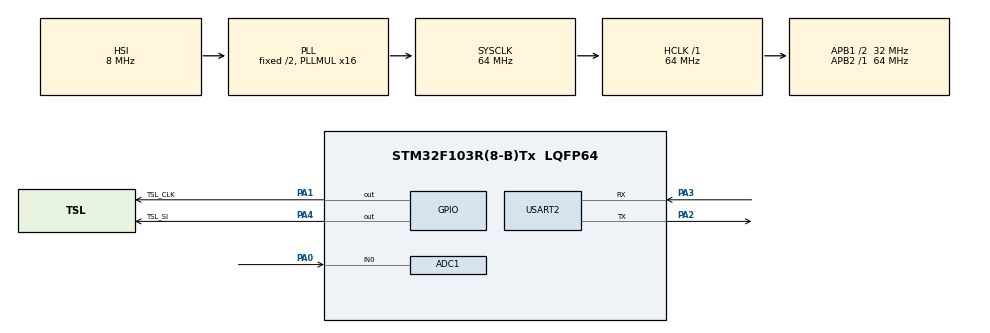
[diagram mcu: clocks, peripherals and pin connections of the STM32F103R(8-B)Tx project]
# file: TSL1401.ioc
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ADC1.Channel-0\#ChannelRegularConversion=ADC_CHANNEL_0
ADC1.NbrOfConversionFlag=1
ADC1.Rank-0\#ChannelRegularConversion=1
ADC1.SamplingTime-0\#ChannelRegularConversion=ADC_SAMPLETIME_1CYCLE_5
ADC1.master=1
Dma.Request0=USART2_RX
Dma.Request1=USART2_TX
Dma.USART2_RX.0.Direction=DMA_PERIPH_TO_MEMORY
Dma.USART2_RX.0.Instance=DMA1_Channel6
Dma.USART2_RX.0.MemDataAlignment=DMA_MDATAALIGN_BYTE
Dma.USART2_RX.0.MemInc=DMA_MINC_ENABLE
Dma.USART2_RX.0.Mode=DMA_NORMAL
Dma.USART2_RX.0.PeriphDataAlignment=DMA_PDATAALIGN_BYTE
Dma.USART2_RX.0.PeriphInc=DMA_PINC_DISABLE
Dma.USART2_RX.0.Priority=DMA_PRIORITY_LOW
Dma.USART2_TX.1.Direction=DMA_MEMORY_TO_PERIPH
Dma.USART2_TX.1.Instance=DMA1_Channel7
Dma.USART2_TX.1.MemDataAlignment=DMA_MDATAALIGN_BYTE
Dma.USART2_TX.1.MemInc=DMA_MINC_ENABLE
Dma.USART2_TX.1.Mode=DMA_NORMAL
Dma.USART2_TX.1.PeriphDataAlignment=DMA_PDATAALIGN_BYTE
Dma.USART2_TX.1.PeriphInc=DMA_PINC_DISABLE
Dma.USART2_TX.1.Priority=DMA_PRIORITY_LOW
Mcu.Family=STM32F1
Mcu.Name=STM32F103R(8-B)Tx
Mcu.Package=LQFP64
NVIC.ADC1_2_IRQn=true\:0\:0\:false\:false\:true\:true\:true\:true
NVIC.DMA1_Channel6_IRQn=true\:0\:0\:false\:false\:true\:false\:true\:true
NVIC.DMA1_Channel7_IRQn=true\:0\:0\:false\:false\:true\:false\:true\:true
NVIC.PriorityGroup=NVIC_PRIORITYGROUP_4
NVIC.USART2_IRQn=true\:0\:0\:false\:false\:true\:true\:true\:true
PA0-WKUP.Signal=ADCx_IN0
PA1.GPIO_Label=TSL_CLK
PA1.Signal=GPIO_Output
PA2.Mode=Asynchronous
PA2.Signal=USART2_TX
PA3.Mode=Asynchronous
PA3.Signal=USART2_RX
PA4.GPIO_Label=TSL_SI
PA4.Signal=GPIO_Output
ProjectManager.HeapSize=0x200
ProjectManager.StackSize=0x400
ProjectManager.TargetToolchain=Makefile
RCC.ADCPresc=RCC_ADCPCLK2_DIV8
RCC.AHBFreq_Value=64000000
RCC.APB1CLKDivider=RCC_HCLK_DIV2
RCC.APB1Freq_Value=32000000
RCC.APB1TimFreq_Value=64000000
RCC.APB2Freq_Value=64000000
RCC.APB2TimFreq_Value=64000000
RCC.HCLKFreq_Value=64000000
RCC.PLLMUL=RCC_PLL_MUL16
RCC.SYSCLKFreq_VALUE=64000000
RCC.SYSCLKSource=RCC_SYSCLKSOURCE_PLLCLK
RCC.USBFreq_Value=64000000
SH.ADCx_IN0.0=ADC1_IN0,IN0
USART2.VirtualMode=VM_ASYNC
VP_SYS_VS_ND.Mode=No_Debug
board=custom

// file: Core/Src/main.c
/* USER CODE BEGIN Header */
/**
  ******************************************************************************
  * @file           : main.c
  * @brief          : Main program body
  ******************************************************************************
  * @attention
  *
  * Copyright (c) 2023 STMicroelectronics.
  * All rights reserved.
  *
  * This software is licensed under terms that can be found in the LICENSE file
  * in the root directory of this software component.
  * If no LICENSE file comes with this software, it is provided AS-IS.
  *
  ******************************************************************************
  */
/* USER CODE END Header */
#include "main.h"
#include "adc.h"
#include "dma.h"
#include "usart.h"
#include "gpio.h"

/* USER CODE BEGIN Includes */
#include <TSL1401.h>
/* USER CODE END Includes */

void SystemClock_Config(void);

int main(void)
{

  /* MCU Configuration--------------------------------------------------------*/

  /* Reset of all peripherals, Initializes the Flash interface and the Systick. */
  HAL_Init();

  /* Configure the system clock */
  SystemClock_Config();

  /* Initialize all configured peripherals */
  MX_GPIO_Init();
  MX_DMA_Init();
  MX_ADC1_Init();
  MX_USART2_UART_Init();
  /* USER CODE BEGIN 2 */
  TSL1401Initialize();
  TSL1401EnableAutoExposure();
  TSL1401EnableContinuousExposure();
  /* USER CODE END 2 */

  /* Infinite loop */
  /* USER CODE BEGIN WHILE */
  while (1)
  {
    TSL1401AsyncReadServiceFunction();
    /* USER CODE END WHILE */

  }
}

void SystemClock_Config(void)
{
  RCC_OscInitTypeDef RCC_OscInitStruct = {0};
  RCC_ClkInitTypeDef RCC_ClkInitStruct = {0};
  RCC_PeriphCLKInitTypeDef PeriphClkInit = {0};

  /** Initializes the RCC Oscillators according to the specified parameters
  * in the RCC_OscInitTypeDef structure.
  */
  RCC_OscInitStruct.OscillatorType = RCC_OSCILLATORTYPE_HSI;
  RCC_OscInitStruct.HSIState = RCC_HSI_ON;
  RCC_OscInitStruct.HSICalibrationValue = RCC_HSICALIBRATION_DEFAULT;
  RCC_OscInitStruct.PLL.PLLState = RCC_PLL_ON;
  RCC_OscInitStruct.PLL.PLLSource = RCC_PLLSOURCE_HSI_DIV2;
  RCC_OscInitStruct.PLL.PLLMUL = RCC_PLL_MUL16;
  if (HAL_RCC_OscConfig(&RCC_OscInitStruct) != HAL_OK)
  {
    Error_Handler();
  }

  /** Initializes the CPU, AHB and APB buses clocks
  */
  RCC_ClkInitStruct.ClockType = RCC_CLOCKTYPE_HCLK|RCC_CLOCKTYPE_SYSCLK
                              |RCC_CLOCKTYPE_PCLK1|RCC_CLOCKTYPE_PCLK2;
  RCC_ClkInitStruct.SYSCLKSource = RCC_SYSCLKSOURCE_PLLCLK;
  RCC_ClkInitStruct.AHBCLKDivider = RCC_SYSCLK_DIV1;
  RCC_ClkInitStruct.APB1CLKDivider = RCC_HCLK_DIV2;
  RCC_ClkInitStruct.APB2CLKDivider = RCC_HCLK_DIV1;

  if (HAL_RCC_ClockConfig(&RCC_ClkInitStruct, FLASH_LATENCY_2) != HAL_OK)
  {
    Error_Handler();
  }
  PeriphClkInit.PeriphClockSelection = RCC_PERIPHCLK_ADC;
  PeriphClkInit.AdcClockSelection = RCC_ADCPCLK2_DIV8;
  if (HAL_RCCEx_PeriphCLKConfig(&PeriphClkInit) != HAL_OK)
  {
    Error_Handler();
  }
}

void Error_Handler(void)
{
  __disable_irq();
  while (1)
  {
  }
}
